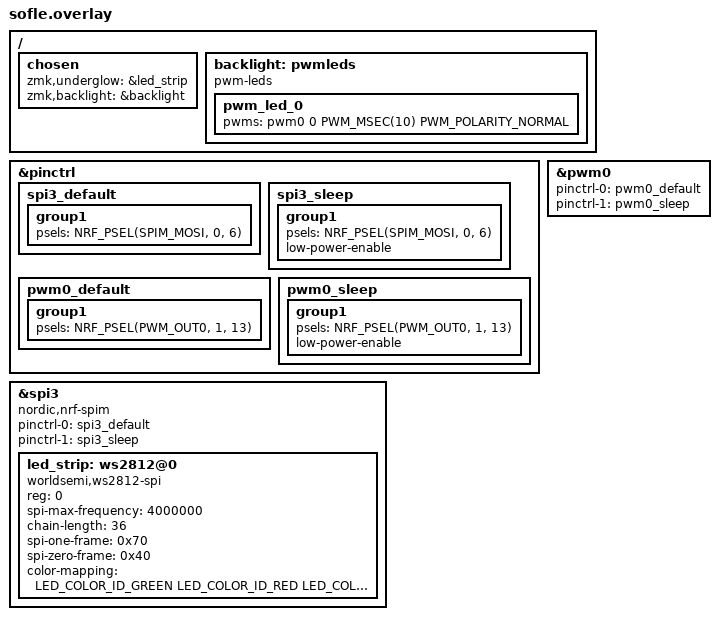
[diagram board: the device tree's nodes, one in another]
/*
 * sofle_left.overlay
 *
 * Hardware overlay para Sofle RGB - Lado Esquerdo
 * Inclui SPI3 (underglow), PWM0 (backlight), Display
 */
#include <dt-bindings/led/led.h>

&pinctrl {
    /* SPI3 — pino de dados do underglow (MOSI = P0.06) */
    spi3_default: spi3_default {
        group1 {
            psels = <NRF_PSEL(SPIM_MOSI, 0, 6)>;
        };
    };
    spi3_sleep: spi3_sleep {
        group1 {
            psels = <NRF_PSEL(SPIM_MOSI, 0, 6)>;
            low-power-enable;
        };
    };
    /* PWM0 — backlight (P1.13) */
    pwm0_default: pwm0_default {
        group1 {
            psels = <NRF_PSEL(PWM_OUT0, 1, 13)>;
        };
    };
    pwm0_sleep: pwm0_sleep {
        group1 {
            psels = <NRF_PSEL(PWM_OUT0, 1, 13)>;
            low-power-enable;
        };
    };
};

&spi3 {
    compatible = "nordic,nrf-spim";
    status = "okay";
    pinctrl-0 = <&spi3_default>;
    pinctrl-1 = <&spi3_sleep>;
    pinctrl-names = "default", "sleep";
    led_strip: ws2812@0 {
        compatible = "worldsemi,ws2812-spi";
        reg = <0>;
        spi-max-frequency = <4000000>;
        chain-length = <36>;
        spi-one-frame  = <0x70>;
        spi-zero-frame = <0x40>;
        color-mapping = 
            LED_COLOR_ID_GREEN
            LED_COLOR_ID_RED
            LED_COLOR_ID_BLUE
        >;
    };
};

&pwm0 {
    status = "okay";
    pinctrl-0 = <&pwm0_default>;
    pinctrl-1 = <&pwm0_sleep>;
    pinctrl-names = "default", "sleep";
};

/ {
    chosen {
        zmk,underglow = &led_strip;
        zmk,backlight  = &backlight;
    };
    backlight: pwmleds {
        compatible = "pwm-leds";
        pwm_led_0 {
            pwms = <&pwm0 0 PWM_MSEC(10) PWM_POLARITY_NORMAL>;
        };
    };
};
